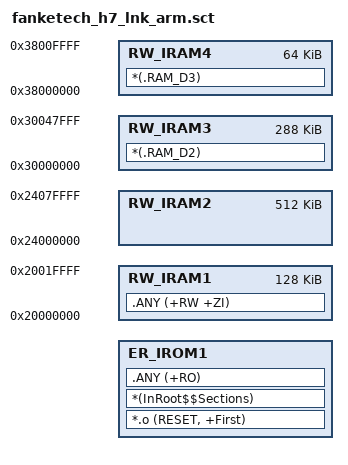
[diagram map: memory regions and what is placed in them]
; *************************************************************
; *** Scatter-Loading Description File generated by uVision ***
; *************************************************************

LR_IROM1 LR_CODE_BASE LR_CODE_SIZE  {    ; load region size_region
	ER_IROM1 LR_CODE_BASE LR_CODE_SIZE  {  ; load address = execution address
		*.o (RESET, +First)
		*(InRoot$$Sections)
		.ANY (+RO)
	}

	RW_IRAM1 0x20000000 0x00020000  {  ; RW data - 128KB DTCM
		.ANY (+RW +ZI)
	}

	RW_IRAM2 0x24000000 0x00080000  {  ; RW data - 512KB AXI SRAM
		*(.RAM_D1) 

        ARM_LIB_STACK 0x24000000+0x00080000 EMPTY 0x00001000 {
            * (STACK);c
		}
	}

	RW_IRAM3 0x30000000 0x00048000  {  ; RW data - 128KB SRAM1(0x30000000) + 128KB SRAM2(0x3002 0000) + 32KB SRAM3(0x30040000)
		*(.RAM_D2)
	}

	RW_IRAM4 0x38000000 0x00010000  {  ; RW data - 64KB SRAM4(0x38000000)
		*(.RAM_D3)
	}
}

_stext ADDR(LR_IROM1);
_etext ADDR(LR_IROM1) + SIZEOF(LR_IROM1);
_sstack ADDR(ARM_LIB_STACK);
_estack ADDR(ARM_LIB_STACK) + SIZEOF(ARM_LIB_STACK);
